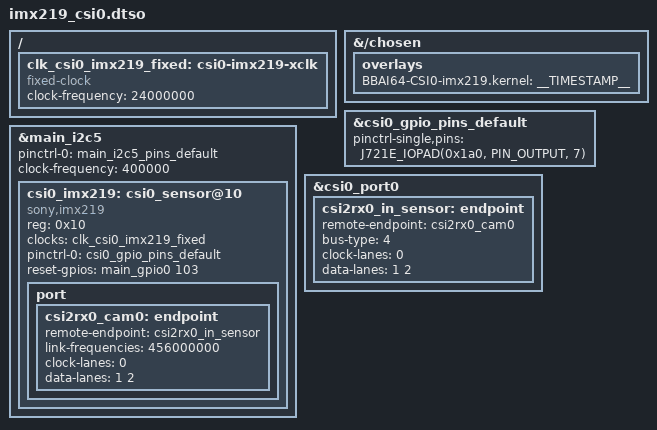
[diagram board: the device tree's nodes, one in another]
/dts-v1/;
/plugin/;

#include <dt-bindings/gpio/gpio.h>
#include <dt-bindings/interrupt-controller/irq.h>

#include "k3-pinctrl.h"

&{/chosen} {
	overlays {
		BBAI64-CSI0-imx219.kernel = __TIMESTAMP__;
	};
};

/ {
	fragment@101 {
		target-path = "/";

		__overlay__ {
			clk_csi0_imx219_fixed: csi0-imx219-xclk {
				compatible = "fixed-clock";
				#clock-cells = <0>;
				clock-frequency = <24000000>;
			};
		};
	};
};

/* The reset pin (W29) set as an output. */
&csi0_gpio_pins_default {
	pinctrl-single,pins = <
		J721E_IOPAD(0x1a0, PIN_OUTPUT, 7) /* basically enable reset as output */
	>;
};

&main_i2c5 {
	status = "okay";

	pinctrl-names = "default";
	pinctrl-0 = <&main_i2c5_pins_default>;

	clock-frequency = <400000>;

	#address-cells = <1>;
	#size-cells = <0>;

	csi0_imx219: csi0_sensor@10 {
		status = "okay";
		compatible = "sony,imx219";
		reg = <0x10>;

		clocks = <&clk_csi0_imx219_fixed>;
		clock-names = "xclk";

		pinctrl-names = "default";
		pinctrl-0 = <&csi0_gpio_pins_default>;

		reset-gpios = <&main_gpio0 103 GPIO_ACTIVE_HIGH>;

		port {
			csi2rx0_cam0: endpoint {
				remote-endpoint = <&csi2rx0_in_sensor>;
				link-frequencies = /bits/ 64 <456000000>;
				clock-lanes = <0>;
				data-lanes = <1 2>;
			};
		};
	};
};

/* Complete the link on the CSI receiver side */
&csi0_port0 {
	status = "okay";

	csi2rx0_in_sensor: endpoint {
		remote-endpoint = <&csi2rx0_cam0>;
		bus-type = <4>; /* CSI2 DPHY. */
		clock-lanes = <0>;
		data-lanes = <1 2>;
	};
};
